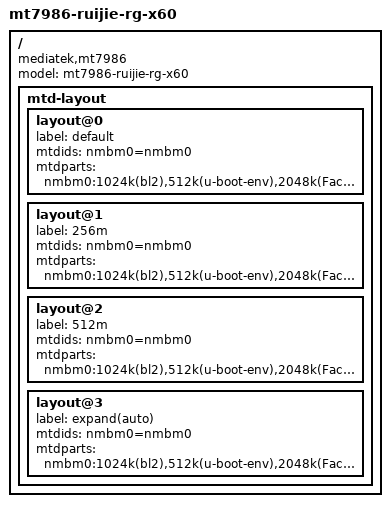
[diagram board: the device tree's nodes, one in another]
// SPDX-License-Identifier: GPL-2.0-or-later

/dts-v1/;
#include "mt7986a-ruijie-rg-x60.dtsi"

/ {
	model = "mt7986-ruijie-rg-x60";
	compatible = "mediatek,mt7986", "mediatek,mt7986-rfb";

	mtd-layout {
		layout@0 {
			label = "default";
			// stock layout, identical to CONFIG_MTDPARTS_DEFAULT
			mtdids = "nmbm0=nmbm0";
			mtdparts = "nmbm0:1024k(bl2),512k(u-boot-env),2048k(Factory),2048k(fip),512k(product_info),512k(kdump),109568k(ubi)";
		};

		layout@1 {
			label = "256m";
			// for 256M spi-nand
			mtdids = "nmbm0=nmbm0";
			mtdparts = "nmbm0:1024k(bl2),512k(u-boot-env),2048k(Factory),2048k(fip),512k(product_info),512k(kdump),239104k(ubi)";
		};

		layout@2 {
			label = "512m";
			// for 512M spi-nand
			mtdids = "nmbm0=nmbm0";
			mtdparts = "nmbm0:1024k(bl2),512k(u-boot-env),2048k(Factory),2048k(fip),512k(product_info),512k(kdump),484864k(ubi)";
		};

		layout@3 {
			label = "expand(auto)";
			// ubi fills the whole flash, fits 128M/256M/512M
			mtdids = "nmbm0=nmbm0";
			mtdparts = "nmbm0:1024k(bl2),512k(u-boot-env),2048k(Factory),2048k(fip),512k(product_info),512k(kdump),-(ubi)";
		};
	};
};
